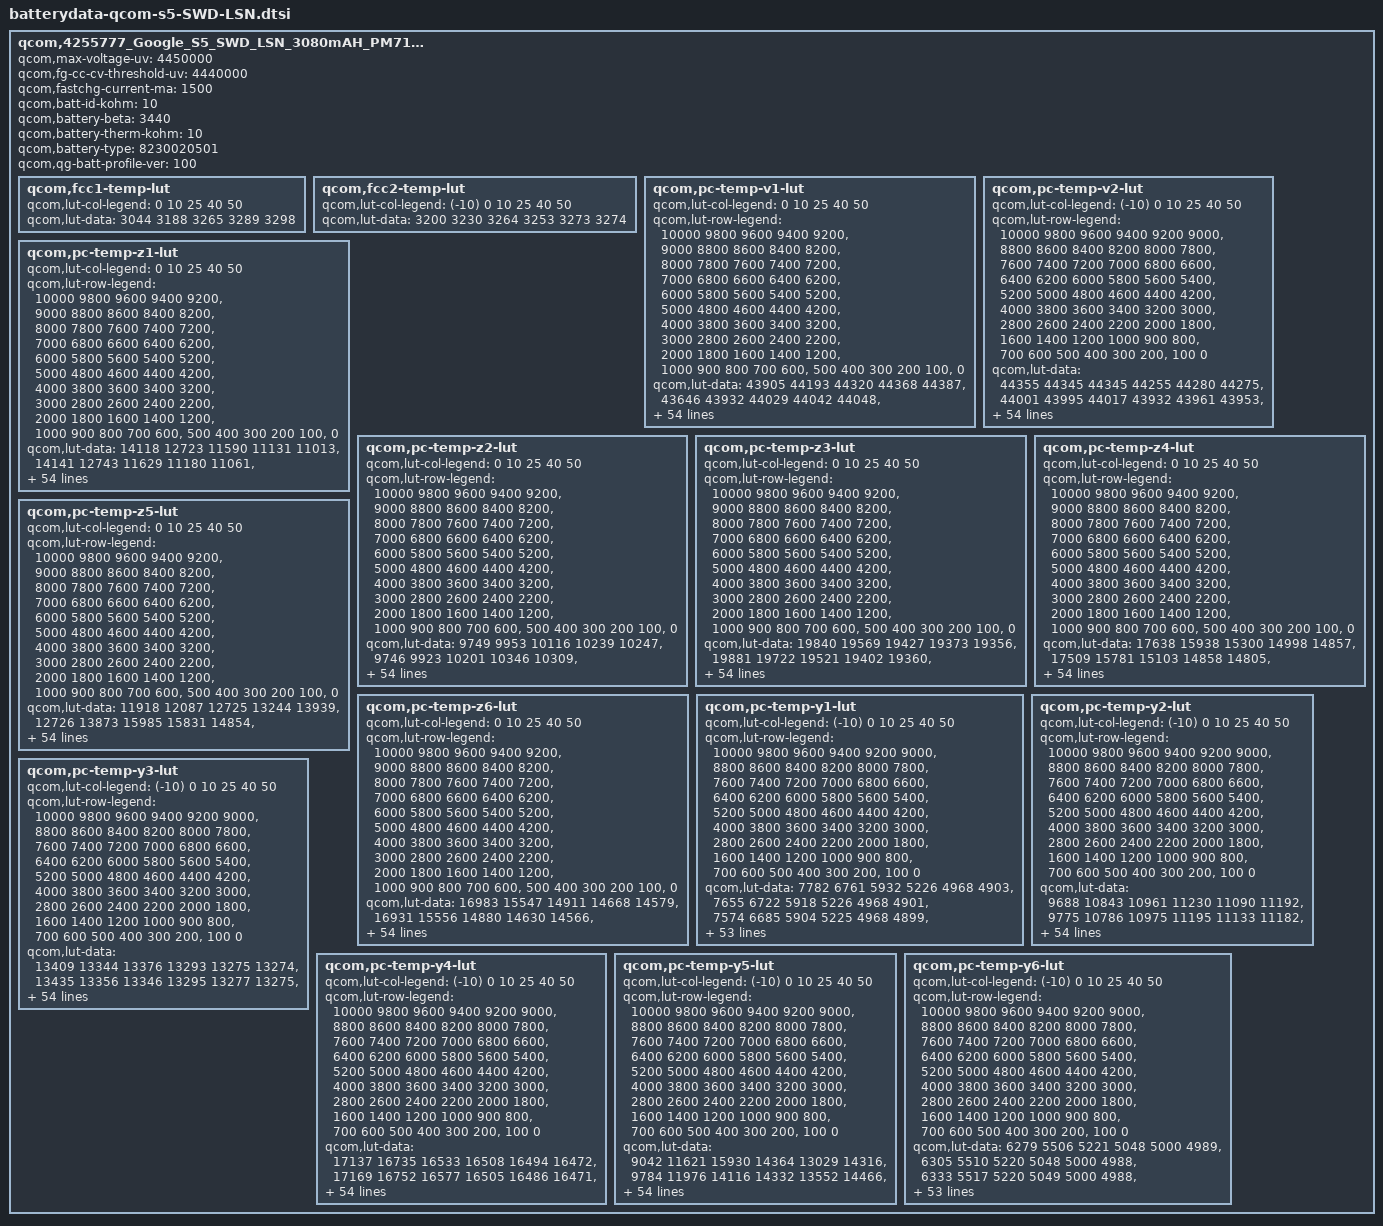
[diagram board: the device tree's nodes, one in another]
qcom,4255777_Google_S5_SWD_LSN_3080mAH_PM7150 {
	/* 4255777_Google_S5_SWD_LSN_3080mAH_PM7150_averaged_MasterSlave_Nov29th2019 */
	qcom,max-voltage-uv = <4450000>;
	qcom,fg-cc-cv-threshold-uv = <4440000>;
	qcom,fastchg-current-ma = <1500>;
	qcom,batt-id-kohm = <10>;
	qcom,battery-beta = <3440>;
	qcom,battery-therm-kohm = <10>;
	qcom,battery-type = "8230020501";
	qcom,qg-batt-profile-ver = <100>;

	qcom,fcc1-temp-lut {
		qcom,lut-col-legend = <0 10 25 40 50>;
		qcom,lut-data = <3044 3188 3265 3289 3298>;
	};

	qcom,fcc2-temp-lut {
		qcom,lut-col-legend = <(-10) 0 10 25 40 50>;
		qcom,lut-data = <3200 3230 3264 3253 3273 3274>;
	};

	qcom,pc-temp-v1-lut {
		qcom,lut-col-legend = <0 10 25 40 50>;
		qcom,lut-row-legend = <10000 9800 9600 9400 9200>,
			<9000 8800 8600 8400 8200>,
			<8000 7800 7600 7400 7200>,
			<7000 6800 6600 6400 6200>,
			<6000 5800 5600 5400 5200>,
			<5000 4800 4600 4400 4200>,
			<4000 3800 3600 3400 3200>,
			<3000 2800 2600 2400 2200>,
			<2000 1800 1600 1400 1200>,
			<1000 900 800 700 600>,
			<500 400 300 200 100>,
			<0>;
		qcom,lut-data = <43905 44193 44320 44368 44387>,
			<43646 43932 44029 44042 44048>,
			<43385 43682 43787 43791 43786>,
			<43121 43444 43556 43562 43558>,
			<42857 43207 43317 43334 43328>,
			<42599 42958 43068 43093 43096>,
			<42345 42705 42819 42849 42857>,
			<42097 42455 42567 42601 42610>,
			<41857 42207 42316 42353 42362>,
			<41624 41963 42067 42103 42117>,
			<41396 41723 41822 41856 41875>,
			<41173 41487 41582 41617 41634>,
			<40956 41259 41348 41382 41396>,
			<40749 41036 41120 41152 41164>,
			<40548 40818 40898 40928 40938>,
			<40358 40605 40684 40711 40720>,
			<40176 40401 40476 40501 40511>,
			<40002 40211 40279 40301 40311>,
			<39836 40031 40096 40114 40122>,
			<39678 39857 39920 39935 39941>,
			<39528 39690 39753 39761 39764>,
			<39384 39528 39592 39595 39595>,
			<39248 39375 39400 39413 39415>,
			<39119 39222 39129 39174 39188>,
			<38996 39052 38889 38940 38958>,
			<38880 38860 38751 38789 38796>,
			<38771 38696 38646 38677 38669>,
			<38670 38565 38546 38568 38557>,
			<38579 38456 38454 38461 38454>,
			<38496 38367 38370 38364 38360>,
			<38424 38293 38293 38278 38272>,
			<38359 38230 38223 38201 38192>,
			<38304 38176 38162 38133 38121>,
			<38256 38131 38108 38072 38056>,
			<38216 38096 38062 38020 37998>,
			<38176 38066 38024 37974 37947>,
			<38138 38034 37984 37928 37892>,
			<38098 38001 37945 37878 37826>,
			<38048 37959 37899 37819 37750>,
			<37988 37891 37827 37743 37669>,
			<37913 37800 37722 37643 37579>,
			<37813 37695 37610 37533 37473>,
			<37689 37568 37483 37407 37343>,
			<37536 37422 37334 37259 37193>,
			<37376 37267 37178 37104 37039>,
			<37238 37151 37072 37006 36947>,
			<37186 37113 37042 36978 36919>,
			<37143 37077 37021 36958 36902>,
			<37101 37045 36999 36941 36885>,
			<37057 37007 36961 36900 36835>,
			<36986 36879 36764 36684 36602>,
			<36739 36494 36340 36252 36164>,
			<36223 35896 35759 35682 35591>,
			<35437 35046 34947 34900 34801>,
			<33886 33467 33686 33694 33589>,
			<30000 30000 30000 30000 30000>;
	};

	qcom,pc-temp-v2-lut {
		qcom,lut-col-legend = <(-10) 0 10 25 40 50>;
		qcom,lut-row-legend = <10000 9800 9600 9400 9200 9000>,
			<8800 8600 8400 8200 8000 7800>,
			<7600 7400 7200 7000 6800 6600>,
			<6400 6200 6000 5800 5600 5400>,
			<5200 5000 4800 4600 4400 4200>,
			<4000 3800 3600 3400 3200 3000>,
			<2800 2600 2400 2200 2000 1800>,
			<1600 1400 1200 1000 900 800>,
			<700 600 500 400 300 200>,
			<100 0>;
		qcom,lut-data = <44355 44345 44345 44255 44280 44275>,
			<44001 43995 44017 43932 43961 43953>,
			<43689 43683 43721 43637 43669 43659>,
			<43426 43417 43462 43377 43412 43401>,
			<43206 43188 43235 43145 43183 43172>,
			<42977 42953 43001 42908 42947 42937>,
			<42727 42703 42756 42659 42701 42693>,
			<42472 42453 42510 42411 42454 42447>,
			<42217 42205 42260 42163 42206 42201>,
			<41961 41958 42009 41917 41960 41955>,
			<41710 41714 41764 41675 41718 41714>,
			<41463 41473 41524 41436 41478 41475>,
			<41217 41232 41288 41204 41245 41243>,
			<40969 40989 41054 40978 41017 41013>,
			<40721 40747 40825 40759 40796 40792>,
			<40478 40506 40600 40547 40582 40579>,
			<40235 40266 40378 40341 40374 40374>,
			<40002 40033 40150 40146 40176 40176>,
			<39780 39807 39912 39964 39989 39988>,
			<39569 39595 39682 39772 39804 39804>,
			<39373 39404 39463 39552 39626 39631>,
			<39188 39226 39259 39326 39439 39451>,
			<39013 39056 39079 39114 39209 39219>,
			<38844 38894 38915 38911 38962 38966>,
			<38686 38744 38765 38745 38780 38782>,
			<38539 38608 38628 38611 38641 38646>,
			<38401 38481 38503 38493 38520 38526>,
			<38270 38364 38390 38386 38410 38415>,
			<38142 38255 38287 38288 38312 38315>,
			<38036 38150 38191 38197 38222 38222>,
			<37953 38050 38102 38114 38140 38136>,
			<37882 37960 38019 38039 38065 38060>,
			<37820 37883 37942 37973 37997 37993>,
			<37764 37815 37871 37909 37931 37927>,
			<37709 37756 37804 37846 37870 37864>,
			<37652 37705 37742 37783 37806 37795>,
			<37594 37657 37689 37716 37719 37695>,
			<37536 37611 37643 37644 37611 37567>,
			<37474 37563 37591 37570 37514 37458>,
			<37408 37508 37529 37497 37428 37367>,
			<37336 37442 37455 37419 37350 37288>,
			<37260 37358 37364 37333 37270 37209>,
			<37177 37253 37262 37215 37150 37089>,
			<37083 37132 37138 37098 37032 36971>,
			<36981 36999 36981 36933 36878 36821>,
			<36854 36895 36886 36879 36835 36782>,
			<36783 36843 36853 36867 36821 36768>,
			<36706 36790 36820 36851 36805 36750>,
			<36617 36733 36780 36820 36777 36722>,
			<36504 36658 36717 36757 36703 36638>,
			<36336 36531 36546 36531 36422 36330>,
			<36070 36245 36095 36042 35931 35833>,
			<35571 35702 35379 35387 35275 35174>,
			<34436 34269 34394 34468 34359 34255>,
			<32847 32695 32391 33002 32911 32789>,
			<30279 31619 29790 28145 28395 28310>;
	};

	qcom,pc-temp-z1-lut {
		qcom,lut-col-legend = <0 10 25 40 50>;
		qcom,lut-row-legend = <10000 9800 9600 9400 9200>,
			<9000 8800 8600 8400 8200>,
			<8000 7800 7600 7400 7200>,
			<7000 6800 6600 6400 6200>,
			<6000 5800 5600 5400 5200>,
			<5000 4800 4600 4400 4200>,
			<4000 3800 3600 3400 3200>,
			<3000 2800 2600 2400 2200>,
			<2000 1800 1600 1400 1200>,
			<1000 900 800 700 600>,
			<500 400 300 200 100>,
			<0>;
		qcom,lut-data = <14118 12723 11590 11131 11013>,
			<14141 12743 11629 11180 11061>,
			<14150 12717 11630 11181 11064>,
			<14147 12717 11608 11178 11063>,
			<14137 12715 11600 11173 11060>,
			<14123 12696 11595 11172 11061>,
			<14097 12666 11592 11172 11061>,
			<14061 12640 11589 11171 11060>,
			<14004 12615 11586 11170 11060>,
			<13927 12601 11584 11170 11060>,
			<13861 12596 11583 11170 11060>,
			<13792 12593 11582 11170 11061>,
			<13737 12595 11582 11170 11062>,
			<13699 12607 11583 11170 11062>,
			<13668 12614 11584 11170 11062>,
			<13658 12615 11585 11170 11062>,
			<13660 12617 11586 11171 11063>,
			<13669 12627 11589 11172 11063>,
			<13688 12642 11591 11173 11064>,
			<13718 12653 11595 11175 11066>,
			<13735 12662 11600 11176 11067>,
			<13743 12673 11604 11178 11068>,
			<13749 12683 11609 11180 11069>,
			<13763 12693 11614 11182 11071>,
			<13785 12705 11619 11184 11074>,
			<13791 12719 11624 11187 11077>,
			<13774 12726 11629 11191 11080>,
			<13759 12726 11634 11195 11083>,
			<13772 12728 11639 11197 11086>,
			<13805 12737 11645 11200 11088>,
			<13822 12753 11653 11202 11090>,
			<13826 12769 11661 11205 11092>,
			<13831 12798 11665 11208 11093>,
			<13849 12818 11668 11211 11095>,
			<13886 12815 11674 11215 11097>,
			<13909 12809 11688 11219 11100>,
			<13915 12811 11699 11223 11104>,
			<13923 12830 11705 11227 11106>,
			<13950 12849 11711 11230 11108>,
			<14015 12859 11720 11233 11111>,
			<14063 12869 11730 11236 11114>,
			<14084 12894 11737 11238 11116>,
			<14101 12936 11741 11241 11116>,
			<14120 12947 11747 11244 11118>,
			<14133 12945 11753 11246 11120>,
			<14099 12961 11756 11250 11119>,
			<14130 12960 11759 11251 11121>,
			<14087 12955 11761 11249 11121>,
			<14179 12969 11761 11250 11122>,
			<14105 12955 11775 11256 11125>,
			<14190 12961 11786 11262 11130>,
			<14205 12982 11797 11271 11137>,
			<14176 13026 11821 11283 11147>,
			<14211 13039 11860 11301 11160>,
			<14211 13039 11860 11301 11160>,
			<14211 13039 11860 11301 11160>;
	};

	qcom,pc-temp-z2-lut {
		qcom,lut-col-legend = <0 10 25 40 50>;
		qcom,lut-row-legend = <10000 9800 9600 9400 9200>,
			<9000 8800 8600 8400 8200>,
			<8000 7800 7600 7400 7200>,
			<7000 6800 6600 6400 6200>,
			<6000 5800 5600 5400 5200>,
			<5000 4800 4600 4400 4200>,
			<4000 3800 3600 3400 3200>,
			<3000 2800 2600 2400 2200>,
			<2000 1800 1600 1400 1200>,
			<1000 900 800 700 600>,
			<500 400 300 200 100>,
			<0>;
		qcom,lut-data = <9749 9953 10116 10239 10247>,
			<9746 9923 10201 10346 10309>,
			<9746 10002 10231 10410 10345>,
			<9759 10016 10173 10398 10334>,
			<9782 10023 10130 10344 10407>,
			<9805 10031 10111 10334 10385>,
			<9856 10037 10115 10332 10368>,
			<9892 10038 10132 10333 10359>,
			<9899 10037 10147 10337 10348>,
			<9903 10036 10161 10352 10315>,
			<9909 10037 10176 10367 10279>,
			<9917 10038 10195 10366 10277>,
			<9925 10034 10215 10361 10286>,
			<9934 10018 10235 10352 10295>,
			<9943 10006 10254 10331 10305>,
			<9944 9999 10269 10319 10319>,
			<9939 9994 10282 10332 10345>,
			<9932 10023 10295 10353 10377>,
			<9924 10090 10311 10376 10399>,
			<9914 10107 10326 10407 10417>,
			<9912 10069 10333 10421 10423>,
			<9918 10042 10338 10431 10425>,
			<9927 10054 10338 10432 10428>,
			<9935 10072 10318 10385 10465>,
			<9944 10088 10296 10330 10515>,
			<9957 10102 10284 10374 10518>,
			<9987 10108 10273 10500 10508>,
			<10026 10107 10276 10528 10485>,
			<10070 10106 10300 10463 10382>,
			<10124 10107 10317 10403 10300>,
			<10175 10112 10327 10373 10282>,
			<10230 10116 10332 10354 10272>,
			<10269 10121 10325 10357 10279>,
			<10213 10127 10310 10372 10311>,
			<10017 10132 10307 10394 10346>,
			<9898 10138 10310 10440 10388>,
			<9734 10147 10314 10484 10435>,
			<9544 10161 10323 10517 10492>,
			<9478 10174 10336 10542 10542>,
			<9431 10184 10358 10555 10547>,
			<9412 10193 10386 10565 10537>,
			<9417 10200 10390 10564 10532>,
			<9428 10208 10375 10544 10536>,
			<9458 10228 10373 10543 10522>,
			<9457 10295 10390 10553 10492>,
			<9450 10552 10477 10527 10544>,
			<9449 10602 10482 10503 10516>,
			<9437 10639 10515 10492 10532>,
			<9445 10643 10658 10542 10565>,
			<9431 10629 10624 10658 10651>,
			<9383 10575 10670 10599 10515>,
			<9423 10442 10684 10470 10367>,
			<9455 10248 10554 10356 10307>,
			<9977 10105 10261 10262 10201>,
			<9977 10105 10261 10262 10201>,
			<9977 10105 10261 10262 10201>;
	};

	qcom,pc-temp-z3-lut {
		qcom,lut-col-legend = <0 10 25 40 50>;
		qcom,lut-row-legend = <10000 9800 9600 9400 9200>,
			<9000 8800 8600 8400 8200>,
			<8000 7800 7600 7400 7200>,
			<7000 6800 6600 6400 6200>,
			<6000 5800 5600 5400 5200>,
			<5000 4800 4600 4400 4200>,
			<4000 3800 3600 3400 3200>,
			<3000 2800 2600 2400 2200>,
			<2000 1800 1600 1400 1200>,
			<1000 900 800 700 600>,
			<500 400 300 200 100>,
			<0>;
		qcom,lut-data = <19840 19569 19427 19373 19356>,
			<19881 19722 19521 19402 19360>,
			<19918 19836 19511 19403 19366>,
			<19956 19829 19592 19446 19381>,
			<19989 19817 19602 19465 19431>,
			<20006 19798 19605 19461 19420>,
			<20017 19768 19596 19453 19413>,
			<20023 19744 19569 19438 19411>,
			<20019 19720 19549 19428 19408>,
			<20009 19705 19535 19424 19396>,
			<19997 19696 19521 19421 19381>,
			<19980 19691 19506 19410 19375>,
			<19961 19689 19492 19391 19371>,
			<19940 19689 19484 19383 19368>,
			<19918 19689 19478 19378 19367>,
			<19898 19690 19474 19376 19364>,
			<19877 19692 19472 19375 19358>,
			<19860 19693 19470 19375 19349>,
			<19847 19693 19465 19375 19345>,
			<19835 19688 19460 19373 19342>,
			<19823 19662 19460 19372 19342>,
			<19810 19642 19461 19373 19346>,
			<19796 19641 19465 19373 19349>,
			<19781 19641 19490 19369 19340>,
			<19765 19651 19510 19364 19328>,
			<19757 19690 19500 19363 19340>,
			<19760 19711 19480 19361 19381>,
			<19770 19706 19468 19365 19394>,
			<19782 19697 19459 19397 19386>,
			<19798 19691 19456 19418 19378>,
			<19804 19685 19460 19415 19374>,
			<19788 19680 19467 19410 19371>,
			<19757 19676 19475 19405 19367>,
			<19700 19672 19482 19399 19363>,
			<19597 19665 19484 19394 19358>,
			<19525 19654 19483 19389 19352>,
			<19488 19645 19482 19386 19349>,
			<19458 19637 19478 19383 19352>,
			<19429 19631 19473 19382 19356>,
			<19399 19629 19470 19380 19355>,
			<19384 19627 19468 19378 19350>,
			<19382 19621 19464 19375 19347>,
			<19380 19608 19461 19371 19346>,
			<19378 19588 19458 19370 19348>,
			<19364 19556 19453 19370 19351>,
			<19355 19379 19430 19355 19336>,
			<19353 19317 19421 19355 19335>,
			<19343 19309 19405 19353 19331>,
			<19342 19300 19373 19347 19323>,
			<19342 19294 19382 19330 19321>,
			<19320 19300 19370 19341 19329>,
			<19352 19329 19356 19354 19341>,
			<19399 19519 19364 19368 19346>,
			<19691 19576 19446 19376 19363>,
			<19691 19576 19446 19376 19363>,
			<19691 19576 19446 19376 19363>;
	};

	qcom,pc-temp-z4-lut {
		qcom,lut-col-legend = <0 10 25 40 50>;
		qcom,lut-row-legend = <10000 9800 9600 9400 9200>,
			<9000 8800 8600 8400 8200>,
			<8000 7800 7600 7400 7200>,
			<7000 6800 6600 6400 6200>,
			<6000 5800 5600 5400 5200>,
			<5000 4800 4600 4400 4200>,
			<4000 3800 3600 3400 3200>,
			<3000 2800 2600 2400 2200>,
			<2000 1800 1600 1400 1200>,
			<1000 900 800 700 600>,
			<500 400 300 200 100>,
			<0>;
		qcom,lut-data = <17638 15938 15300 14998 14857>,
			<17509 15781 15103 14858 14805>,
			<17303 16447 14936 14796 14759>,
			<16951 16136 15161 14838 14753>,
			<16519 15766 15078 14870 14811>,
			<16219 15582 14963 14812 14779>,
			<15994 15445 14906 14792 14760>,
			<15817 15342 14866 14788 14750>,
			<15679 15264 14846 14783 14746>,
			<15567 15195 14836 14772 14747>,
			<15478 15125 14829 14762 14748>,
			<15405 15063 14824 14763 14746>,
			<15343 15023 14819 14766 14738>,
			<15286 14993 14811 14766 14730>,
			<15237 14965 14800 14758 14721>,
			<15216 14937 14788 14749 14713>,
			<15205 14910 14777 14739 14710>,
			<15200 14879 14766 14728 14708>,
			<15199 14844 14758 14718 14703>,
			<15199 14833 14751 14709 14695>,
			<15199 14845 14744 14707 14693>,
			<15203 14852 14737 14708 14694>,
			<15208 14841 14741 14712 14695>,
			<15218 14828 14813 14786 14760>,
			<15235 14827 14874 14875 14851>,
			<15244 14832 14874 14878 14843>,
			<15238 14840 14870 14861 14785>,
			<15227 14857 14865 14835 14754>,
			<15209 14872 14853 14784 14745>,
			<15182 14872 14838 14745 14738>,
			<15173 14868 14818 14730 14727>,
			<15182 14862 14796 14721 14716>,
			<15201 14853 14776 14715 14707>,
			<15252 14841 14758 14710 14699>,
			<15360 14829 14746 14708 14697>,
			<15421 14817 14736 14709 14698>,
			<15435 14804 14731 14709 14701>,
			<15438 14791 14727 14713 14710>,
			<15427 14779 14725 14719 14721>,
			<15401 14768 14727 14722 14721>,
			<15371 14759 14732 14724 14718>,
			<15333 14754 14732 14723 14713>,
			<15289 14751 14720 14712 14702>,
			<15247 14752 14712 14709 14698>,
			<15131 14747 14704 14708 14697>,
			<15077 14863 14676 14684 14679>,
			<15080 14930 14678 14675 14670>,
			<15080 14931 14681 14659 14657>,
			<15077 14932 14701 14649 14642>,
			<15071 14930 14686 14659 14640>,
			<15086 14926 14714 14668 14655>,
			<15074 14935 14746 14665 14652>,
			<15100 14770 14744 14652 14649>,
			<14890 14813 14679 14652 14642>,
			<14890 14813 14679 14652 14642>,
			<14890 14813 14679 14652 14642>;
	};

	qcom,pc-temp-z5-lut {
		qcom,lut-col-legend = <0 10 25 40 50>;
		qcom,lut-row-legend = <10000 9800 9600 9400 9200>,
			<9000 8800 8600 8400 8200>,
			<8000 7800 7600 7400 7200>,
			<7000 6800 6600 6400 6200>,
			<6000 5800 5600 5400 5200>,
			<5000 4800 4600 4400 4200>,
			<4000 3800 3600 3400 3200>,
			<3000 2800 2600 2400 2200>,
			<2000 1800 1600 1400 1200>,
			<1000 900 800 700 600>,
			<500 400 300 200 100>,
			<0>;
		qcom,lut-data = <11918 12087 12725 13244 13939>,
			<12726 13873 15985 15831 14854>,
			<13624 13147 17440 17496 16998>,
			<14654 13388 15264 18312 18281>,
			<15751 13703 15818 17216 18591>,
			<16793 13937 16527 18010 18581>,
			<17826 14148 16772 18070 18617>,
			<18718 14236 16922 17282 18803>,
			<19425 14235 16926 16839 18926>,
			<20019 14256 16683 17001 18005>,
			<20495 14435 16401 17180 16680>,
			<20940 14704 16073 16714 16522>,
			<21172 14897 15800 15581 16563>,
			<21110 15047 15832 15302 16658>,
			<20923 15278 16035 15395 17008>,
			<20603 15815 16319 15550 17248>,
			<19762 16426 16817 15935 16888>,
			<18841 17210 17334 16475 16375>,
			<18225 18345 17719 17030 16411>,
			<17699 18554 18141 17709 16801>,
			<17200 17839 18773 18298 17417>,
			<16713 17487 19755 19074 18828>,
			<16270 17990 21764 19459 19716>,
			<15857 18952 29164 18604 17544>,
			<15471 22389 34832 17147 14449>,
			<15262 32458 31036 15867 14683>,
			<15320 37464 23647 14616 16481>,
			<15502 35369 20405 14593 17208>,
			<15709 32226 18615 16898 17240>,
			<15962 30202 18087 19204 17301>,
			<16039 28538 18390 20452 17865>,
			<15658 27543 18989 21487 18872>,
			<14998 27015 20320 22517 19955>,
			<14170 26510 22572 23535 21214>,
			<13038 25593 24632 24488 21928>,
			<12293 24567 26795 25522 22261>,
			<11935 24199 27735 26018 22544>,
			<11673 24035 27748 25625 22976>,
			<11427 23980 27665 24814 23351>,
			<11178 25178 27233 23769 22737>,
			<11077 26747 26309 22352 20668>,
			<11090 26315 25721 21459 19889>,
			<11120 24120 25380 20900 20018>,
			<11213 21585 25094 20430 20088>,
			<11489 20517 24913 19894 20009>,
			<11598 14908 25266 19605 18655>,
			<11545 11738 22509 19899 18975>,
			<11438 11613 18865 20825 19280>,
			<11395 11479 15739 20762 19793>,
			<11387 11425 17027 17007 19753>,
			<11252 11524 15187 16963 17556>,
			<11448 11783 13478 17685 18539>,
			<11898 18648 13654 20485 19332>,
			<19529 18976 23613 22236 26765>,
			<19529 18976 23613 22236 26765>,
			<19529 18976 23613 22236 26765>;
	};

	qcom,pc-temp-z6-lut {
		qcom,lut-col-legend = <0 10 25 40 50>;
		qcom,lut-row-legend = <10000 9800 9600 9400 9200>,
			<9000 8800 8600 8400 8200>,
			<8000 7800 7600 7400 7200>,
			<7000 6800 6600 6400 6200>,
			<6000 5800 5600 5400 5200>,
			<5000 4800 4600 4400 4200>,
			<4000 3800 3600 3400 3200>,
			<3000 2800 2600 2400 2200>,
			<2000 1800 1600 1400 1200>,
			<1000 900 800 700 600>,
			<500 400 300 200 100>,
			<0>;
		qcom,lut-data = <16983 15547 14911 14668 14579>,
			<16931 15556 14880 14630 14566>,
			<16848 15890 14802 14602 14549>,
			<16696 15749 14937 14643 14554>,
			<16504 15576 14906 14669 14606>,
			<16366 15476 14859 14643 14587>,
			<16262 15395 14825 14627 14575>,
			<16172 15332 14795 14617 14570>,
			<16092 15280 14775 14610 14566>,
			<16021 15238 14763 14603 14559>,
			<15955 15203 14752 14597 14553>,
			<15894 15174 14742 14590 14547>,
			<15838 15157 14733 14583 14542>,
			<15783 15146 14724 14577 14537>,
			<15734 15136 14717 14572 14533>,
			<15711 15125 14710 14567 14528>,
			<15699 15115 14703 14562 14522>,
			<15693 15104 14698 14557 14517>,
			<15694 15093 14691 14552 14512>,
			<15699 15085 14686 14547 14508>,
			<15702 15079 14685 14546 14506>,
			<15706 15075 14684 14547 14508>,
			<15709 15073 14687 14549 14511>,
			<15715 15071 14731 14580 14536>,
			<15723 15075 14769 14616 14569>,
			<15729 15100 14765 14617 14572>,
			<15734 15117 14755 14610 14569>,
			<15738 15125 14747 14603 14565>,
			<15742 15129 14738 14598 14558>,
			<15746 15128 14731 14592 14550>,
			<15747 15125 14725 14585 14544>,
			<15746 15123 14721 14578 14537>,
			<15745 15120 14717 14573 14531>,
			<15743 15116 14714 14568 14525>,
			<15741 15111 14711 14564 14522>,
			<15740 15103 14709 14562 14519>,
			<15743 15097 14706 14561 14518>,
			<15747 15091 14704 14562 14523>,
			<15752 15088 14702 14564 14530>,
			<15757 15086 14703 14564 14530>,
			<15760 15085 14705 14564 14527>,
			<15758 15084 14705 14563 14523>,
			<15754 15081 14699 14556 14518>,
			<15742 15076 14695 14555 14517>,
			<15692 15059 14690 14554 14519>,
			<15664 15021 14668 14537 14503>,
			<15665 15019 14664 14533 14499>,
			<15664 15017 14657 14525 14491>,
			<15661 15015 14652 14517 14480>,
			<15664 15016 14652 14514 14479>,
			<15669 15024 14660 14525 14491>,
			<15691 15052 14670 14532 14497>,
			<15738 15093 14681 14537 14501>,
			<15822 15161 14705 14544 14510>,
			<15822 15161 14705 14544 14510>,
			<15822 15161 14705 14544 14510>;
	};

	qcom,pc-temp-y1-lut {
		qcom,lut-col-legend = <(-10) 0 10 25 40 50>;
		qcom,lut-row-legend = <10000 9800 9600 9400 9200 9000>,
			<8800 8600 8400 8200 8000 7800>,
			<7600 7400 7200 7000 6800 6600>,
			<6400 6200 6000 5800 5600 5400>,
			<5200 5000 4800 4600 4400 4200>,
			<4000 3800 3600 3400 3200 3000>,
			<2800 2600 2400 2200 2000 1800>,
			<1600 1400 1200 1000 900 800>,
			<700 600 500 400 300 200>,
			<100 0>;
		qcom,lut-data = <7782 6761 5932 5226 4968 4903>,
			<7655 6722 5918 5226 4968 4901>,
			<7574 6685 5904 5225 4968 4899>,
			<7529 6656 5892 5223 4968 4898>,
			<7510 6636 5884 5222 4968 4898>,
			<7508 6630 5881 5221 4968 4898>,
			<7552 6638 5884 5220 4967 4901>,
			<7597 6648 5886 5218 4965 4902>,
			<7587 6650 5884 5217 4964 4901>,
			<7557 6648 5880 5215 4963 4899>,
			<7547 6644 5876 5213 4963 4899>,
			<7545 6630 5870 5212 4963 4900>,
			<7545 6615 5865 5211 4964 4901>,
			<7538 6600 5859 5209 4963 4899>,
			<7532 6587 5855 5208 4963 4898>,
			<7547 6589 5854 5209 4964 4899>,
			<7577 6599 5854 5210 4965 4900>,
			<7588 6603 5857 5211 4966 4901>,
			<7549 6601 5867 5212 4966 4902>,
			<7507 6599 5872 5214 4966 4902>,
			<7514 6607 5865 5216 4966 4902>,
			<7540 6619 5856 5219 4966 4903>,
			<7553 6622 5856 5220 4967 4903>,
			<7561 6622 5858 5221 4969 4903>,
			<7565 6623 5859 5223 4970 4903>,
			<7571 6632 5859 5226 4968 4904>,
			<7581 6642 5861 5228 4966 4905>,
			<7578 6642 5865 5231 4970 4905>,
			<7556 6639 5871 5233 4974 4906>,
			<7546 6639 5876 5235 4976 4907>,
			<7539 6641 5887 5237 4978 4908>,
			<7525 6643 5890 5240 4979 4910>,
			<7511 6645 5891 5244 4979 4911>,
			<7499 6649 5892 5248 4980 4913>,
			<7495 6648 5891 5250 4983 4915>,
			<7498 6646 5887 5251 4986 4916>,
			<7501 6645 5888 5254 4986 4917>,
			<7499 6642 5891 5259 4985 4917>,
			<7498 6641 5893 5262 4986 4917>,
			<7505 6652 5900 5263 4986 4918>,
			<7524 6669 5904 5264 4988 4919>,
			<7514 6673 5907 5265 4992 4922>,
			<7512 6686 5911 5269 4990 4922>,
			<7565 6647 5912 5275 4995 4924>,
			<7538 6683 5942 5279 4996 4926>,
			<7567 6678 5926 5284 4998 4927>,
			<7570 6697 5934 5284 5000 4928>,
			<7544 6690 5953 5286 5002 4928>,
			<7546 6697 5959 5291 5001 4928>,
			<7559 6696 5955 5295 5004 4928>,
			<7540 6699 5962 5298 5004 4931>,
			<7590 6693 5981 5313 5011 4936>,
			<7691 6804 5993 5334 5020 4943>,
			<8136 7126 6131 5374 5034 4957>,
			<8136 7126 6131 5374 5034 4957>,
			<8136 7126 6131 5374 5034 4957>;
	};

	qcom,pc-temp-y2-lut {
		qcom,lut-col-legend = <(-10) 0 10 25 40 50>;
		qcom,lut-row-legend = <10000 9800 9600 9400 9200 9000>,
			<8800 8600 8400 8200 8000 7800>,
			<7600 7400 7200 7000 6800 6600>,
			<6400 6200 6000 5800 5600 5400>,
			<5200 5000 4800 4600 4400 4200>,
			<4000 3800 3600 3400 3200 3000>,
			<2800 2600 2400 2200 2000 1800>,
			<1600 1400 1200 1000 900 800>,
			<700 600 500 400 300 200>,
			<100 0>;
		qcom,lut-data = <9688 10843 10961 11230 11090 11192>,
			<9775 10786 10975 11195 11133 11182>,
			<9943 10726 10969 11160 11147 11168>,
			<10132 10669 10947 11126 11144 11151>,
			<10282 10623 10913 11093 11131 11133>,
			<10335 10592 10869 11063 11115 11114>,
			<10340 10568 10798 11034 11070 11073>,
			<10345 10555 10742 11008 11038 11040>,
			<10355 10554 10725 10981 11056 11030>,
			<10372 10553 10714 10956 11084 11018>,
			<10387 10554 10700 10954 11078 10990>,
			<10402 10558 10684 10963 11036 10928>,
			<10417 10565 10678 10967 11010 10905>,
			<10435 10577 10680 10934 11000 10941>,
			<10454 10594 10684 10901 10991 10974>,
			<10470 10609 10693 10900 10976 10968>,
			<10486 10625 10711 10904 10961 10953>,
			<10498 10643 10730 10915 10967 10956>,
			<10505 10668 10752 10961 11014 10976>,
			<10511 10688 10776 10988 11071 11008>,
			<10517 10699 10801 10982 11154 11096>,
			<10522 10707 10829 10973 11213 11173>,
			<10525 10721 10862 10992 11193 11168>,
			<10526 10743 10898 11051 11150 11141>,
			<10527 10758 10922 11086 11145 11137>,
			<10524 10766 10942 11107 11169 11141>,
			<10514 10772 10953 11120 11193 11153>,
			<10409 10775 10948 11122 11211 11189>,
			<9990 10779 10940 11123 11224 11237>,
			<9750 10785 10936 11126 11230 11282>,
			<9719 10799 10928 11131 11235 11326>,
			<9703 10809 10925 11132 11245 11349>,
			<9693 10811 10922 11124 11265 11361>,
			<9686 10811 10918 11113 11277 11373>,
			<9681 10807 10923 11098 11259 11389>,
			<9676 10795 10932 11078 11238 11400>,
			<9672 10779 10926 11068 11244 11368>,
			<9668 10749 10902 11061 11259 11293>,
			<9665 10714 10889 11058 11256 11267>,
			<9662 10685 10882 11073 11238 11261>,
			<9659 10654 10871 11081 11200 11235>,
			<9658 10611 10851 11067 11155 11211>,
			<9656 10552 10836 11040 11207 11238>,
			<9656 10560 10861 11068 11225 11242>,
			<9655 10459 10853 11186 11157 11184>,
			<9654 10335 10798 11140 11104 11120>,
			<9653 10089 10728 11025 11147 11095>,
			<9653 9751 10647 10997 11107 11119>,
			<9652 9680 10566 10968 11088 11041>,
			<9652 9663 10465 10969 11022 11001>,
			<9651 9655 10307 10939 11031 10982>,
			<9650 9651 9778 10908 10990 10889>,
			<9649 9648 9654 10752 10895 10825>,
			<9648 9647 9649 10600 10826 10708>,
			<9648 9647 9649 10600 10826 10708>,
			<9648 9647 9649 10600 10826 10708>;
	};

	qcom,pc-temp-y3-lut {
		qcom,lut-col-legend = <(-10) 0 10 25 40 50>;
		qcom,lut-row-legend = <10000 9800 9600 9400 9200 9000>,
			<8800 8600 8400 8200 8000 7800>,
			<7600 7400 7200 7000 6800 6600>,
			<6400 6200 6000 5800 5600 5400>,
			<5200 5000 4800 4600 4400 4200>,
			<4000 3800 3600 3400 3200 3000>,
			<2800 2600 2400 2200 2000 1800>,
			<1600 1400 1200 1000 900 800>,
			<700 600 500 400 300 200>,
			<100 0>;
		qcom,lut-data = <13409 13344 13376 13293 13275 13274>,
			<13435 13356 13346 13295 13277 13275>,
			<13481 13371 13329 13297 13279 13276>,
			<13532 13384 13320 13299 13281 13278>,
			<13572 13395 13317 13300 13282 13279>,
			<13587 13401 13318 13302 13283 13280>,
			<13590 13404 13333 13303 13284 13281>,
			<13591 13407 13345 13303 13284 13282>,
			<13590 13412 13344 13303 13285 13282>,
			<13588 13419 13343 13303 13286 13283>,
			<13587 13425 13345 13302 13286 13283>,
			<13587 13431 13355 13301 13285 13283>,
			<13587 13433 13362 13301 13285 13283>,
			<13580 13432 13365 13305 13289 13283>,
			<13566 13429 13368 13311 13293 13283>,
			<13557 13426 13371 13314 13292 13285>,
			<13549 13421 13373 13316 13290 13288>,
			<13541 13415 13373 13318 13291 13289>,
			<13532 13406 13368 13321 13294 13288>,
			<13523 13400 13361 13322 13296 13288>,
			<13515 13398 13354 13319 13299 13291>,
			<13508 13396 13346 13315 13301 13295>,
			<13500 13393 13341 13310 13297 13290>,
			<13490 13387 13337 13302 13289 13279>,
			<13482 13383 13334 13299 13284 13277>,
			<13475 13383 13331 13298 13281 13277>,
			<13469 13382 13329 13298 13280 13278>,
			<13456 13382 13332 13299 13280 13277>,
			<13429 13382 13336 13300 13280 13277>,
			<13417 13381 13338 13301 13281 13277>,
			<13419 13374 13340 13301 13282 13276>,
			<13425 13369 13341 13301 13282 13276>,
			<13435 13369 13341 13304 13283 13277>,
			<13457 13369 13341 13306 13283 13278>,
			<13478 13369 13340 13305 13284 13278>,
			<13497 13370 13338 13304 13285 13279>,
			<13522 13371 13339 13303 13284 13278>,
			<13562 13380 13341 13302 13281 13277>,
			<13617 13389 13342 13302 13280 13276>,
			<13676 13395 13342 13302 13281 13276>,
			<13743 13400 13342 13302 13281 13276>,
			<13830 13405 13341 13302 13280 13277>,
			<13921 13405 13343 13301 13281 13276>,
			<13935 13384 13334 13300 13281 13277>,
			<13970 13368 13333 13289 13282 13276>,
			<14192 13392 13332 13289 13283 13278>,
			<14357 13405 13335 13301 13283 13279>,
			<14566 13435 13344 13306 13286 13281>,
			<14827 13524 13359 13305 13290 13286>,
			<15140 13670 13379 13310 13291 13287>,
			<15538 14079 13403 13308 13285 13283>,
			<16301 15343 13488 13306 13287 13284>,
			<20565 22338 14644 13315 13289 13286>,
			<46869 65535 26276 13332 13298 13291>,
			<46869 65535 26276 13332 13298 13291>,
			<46869 65535 26276 13332 13298 13291>;
	};

	qcom,pc-temp-y4-lut {
		qcom,lut-col-legend = <(-10) 0 10 25 40 50>;
		qcom,lut-row-legend = <10000 9800 9600 9400 9200 9000>,
			<8800 8600 8400 8200 8000 7800>,
			<7600 7400 7200 7000 6800 6600>,
			<6400 6200 6000 5800 5600 5400>,
			<5200 5000 4800 4600 4400 4200>,
			<4000 3800 3600 3400 3200 3000>,
			<2800 2600 2400 2200 2000 1800>,
			<1600 1400 1200 1000 900 800>,
			<700 600 500 400 300 200>,
			<100 0>;
		qcom,lut-data = <17137 16735 16533 16508 16494 16472>,
			<17169 16752 16577 16505 16486 16471>,
			<17212 16769 16614 16504 16480 16467>,
			<17256 16784 16641 16504 16476 16464>,
			<17293 16798 16657 16504 16474 16461>,
			<17316 16810 16660 16505 16474 16460>,
			<17335 16821 16645 16510 16476 16460>,
			<17347 16830 16633 16516 16479 16460>,
			<17348 16837 16644 16523 16482 16461>,
			<17347 16842 16666 16533 16486 16464>,
			<17343 16848 16678 16544 16492 16468>,
			<17330 16856 16685 16558 16501 16474>,
			<17314 16860 16695 16570 16507 16480>,
			<17304 16860 16717 16578 16509 16487>,
			<17292 16858 16741 16585 16512 16493>,
			<17269 16854 16759 16601 16522 16498>,
			<17227 16842 16774 16625 16540 16502>,
			<17183 16827 16771 16657 16557 16510>,
			<17143 16806 16740 16708 16574 16525>,
			<17105 16785 16703 16734 16596 16546>,
			<17075 16768 16664 16707 16638 16581>,
			<17050 16752 16630 16658 16669 16607>,
			<17025 16741 16613 16602 16621 16574>,
			<17000 16731 16601 16537 16519 16502>,
			<16975 16723 16597 16513 16490 16478>,
			<16947 16715 16597 16509 16484 16472>,
			<16922 16708 16596 16507 16482 16470>,
			<16929 16702 16592 16508 16485 16472>,
			<16981 16696 16589 16511 16489 16476>,
			<17020 16692 16589 16515 16495 16481>,
			<17035 16690 16591 16522 16502 16490>,
			<17045 16687 16592 16530 16511 16499>,
			<17054 16681 16592 16542 16523 16510>,
			<17063 16675 16593 16550 16533 16519>,
			<17075 16677 16589 16551 16543 16527>,
			<17098 16688 16584 16551 16550 16532>,
			<17125 16700 16585 16547 16537 16520>,
			<17151 16714 16592 16527 16497 16486>,
			<17180 16729 16599 16508 16476 16469>,
			<17215 16750 16604 16494 16468 16463>,
			<17255 16765 16606 16490 16470 16465>,
			<17283 16766 16605 16497 16480 16471>,
			<17296 16757 16594 16490 16470 16464>,
			<17228 16705 16574 16486 16473 16464>,
			<17150 16734 16559 16491 16456 16450>,
			<17200 16754 16577 16503 16468 16461>,
			<17240 16804 16599 16498 16478 16472>,
			<17289 16896 16626 16507 16490 16481>,
			<17354 16971 16665 16536 16504 16502>,
			<17480 17073 16731 16552 16520 16511>,
			<17560 17218 16792 16535 16480 16464>,
			<17633 17397 16896 16516 16477 16466>,
			<18868 18795 17289 16536 16488 16478>,
			<38490 38899 21264 16594 16528 16522>,
			<38490 38899 21264 16594 16528 16522>,
			<38490 38899 21264 16594 16528 16522>;
	};

	qcom,pc-temp-y5-lut {
		qcom,lut-col-legend = <(-10) 0 10 25 40 50>;
		qcom,lut-row-legend = <10000 9800 9600 9400 9200 9000>,
			<8800 8600 8400 8200 8000 7800>,
			<7600 7400 7200 7000 6800 6600>,
			<6400 6200 6000 5800 5600 5400>,
			<5200 5000 4800 4600 4400 4200>,
			<4000 3800 3600 3400 3200 3000>,
			<2800 2600 2400 2200 2000 1800>,
			<1600 1400 1200 1000 900 800>,
			<700 600 500 400 300 200>,
			<100 0>;
		qcom,lut-data = <9042 11621 15930 14364 13029 14316>,
			<9784 11976 14116 14332 13552 14466>,
			<10736 12334 12833 14272 13917 14779>,
			<11697 12641 12019 14191 14145 15131>,
			<12468 12846 11609 14094 14257 15400>,
			<12855 12894 11578 13984 14268 15475>,
			<13009 12794 12228 13794 14127 15481>,
			<13121 12701 12763 13550 13930 15483>,
			<13233 12811 12548 13273 13748 15347>,
			<13338 13110 12178 12955 13535 15035>,
			<13513 13421 12214 12614 13231 14701>,
			<13881 13796 12656 12221 12814 14293>,
			<14117 14099 13066 12078 12696 13891>,
			<14102 14308 13320 12361 13220 13430>,
			<14067 14461 13615 12700 13684 13151>,
			<14149 14543 14244 12804 13333 13431>,
			<14474 14587 15101 12876 12685 13946>,
			<14661 14571 15612 13034 12599 13917>,
			<14693 14373 15973 13488 12779 13385>,
			<14703 14223 16095 14139 13093 13168>,
			<14696 14412 15672 15505 14103 14071>,
			<14675 14725 15107 16801 15258 14961>,
			<14621 14707 14792 16570 15958 14852>,
			<14372 14417 14482 15568 16479 14575>,
			<14166 14284 14345 15118 16344 14636>,
			<14078 14420 14020 15020 15130 15270>,
			<13901 14634 13825 15026 14382 15604>,
			<13382 14851 14423 15273 14264 15343>,
			<11907 15072 15265 15626 14249 14924>,
			<11025 15048 15671 15766 14438 14498>,
			<10828 14498 16322 15835 14807 14036>,
			<10731 14099 16731 16035 15042 13990>,
			<10756 14060 17082 17067 15212 14402>,
			<10839 14034 17358 17958 15469 14909>,
			<10880 13980 17166 18034 16442 15439>,
			<10890 13904 16746 18058 17440 15947>,
			<10902 13919 16796 18045 17248 16318>,
			<10967 14533 17141 17950 16532 16648>,
			<11059 15205 17179 17891 16397 16769>,
			<11071 15531 16882 18102 16915 16753>,
			<11050 15760 16584 18109 16604 16516>,
			<11072 15786 16203 17344 15498 16049>,
			<11136 15402 16559 17291 16235 16076>,
			<11110 14183 15330 17085 15311 16145>,
			<11212 12197 15149 13398 17741 17746>,
			<11254 12411 13841 13067 15952 16048>,
			<11284 11963 13547 15607 15064 14975>,
			<11371 11325 13536 16435 15247 14984>,
			<11476 11308 13805 14912 15598 15853>,
			<11444 11316 13898 15196 15139 15332>,
			<11556 11344 13733 15162 14866 16577>,
			<11614 11173 11797 15224 15442 16745>,
			<10436 10564 11098 16017 15803 17163>,
			<9031 9065 10322 16729 18364 18944>,
			<9031 9065 10322 16729 18364 18944>,
			<9031 9065 10322 16729 18364 18944>;
	};

	qcom,pc-temp-y6-lut {
		qcom,lut-col-legend = <(-10) 0 10 25 40 50>;
		qcom,lut-row-legend = <10000 9800 9600 9400 9200 9000>,
			<8800 8600 8400 8200 8000 7800>,
			<7600 7400 7200 7000 6800 6600>,
			<6400 6200 6000 5800 5600 5400>,
			<5200 5000 4800 4600 4400 4200>,
			<4000 3800 3600 3400 3200 3000>,
			<2800 2600 2400 2200 2000 1800>,
			<1600 1400 1200 1000 900 800>,
			<700 600 500 400 300 200>,
			<100 0>;
		qcom,lut-data = <6279 5506 5221 5048 5000 4989>,
			<6305 5510 5220 5048 5000 4988>,
			<6333 5517 5220 5049 5000 4988>,
			<6357 5526 5220 5050 5001 4988>,
			<6373 5533 5220 5051 5001 4988>,
			<6378 5535 5221 5052 5002 4989>,
			<6374 5535 5223 5054 5003 4990>,
			<6366 5535 5227 5056 5004 4991>,
			<6357 5536 5229 5058 5006 4992>,
			<6345 5538 5232 5061 5008 4993>,
			<6333 5540 5237 5064 5010 4994>,
			<6323 5542 5243 5067 5011 4996>,
			<6312 5543 5250 5070 5014 4998>,
			<6298 5539 5257 5075 5017 4999>,
			<6282 5533 5264 5081 5020 5001>,
			<6265 5527 5270 5088 5023 5004>,
			<6245 5520 5275 5096 5027 5007>,
			<6228 5512 5274 5107 5032 5011>,
			<6215 5500 5261 5123 5039 5015>,
			<6203 5490 5245 5131 5047 5020>,
			<6192 5484 5229 5122 5061 5033>,
			<6182 5479 5214 5104 5070 5043>,
			<6172 5473 5205 5084 5054 5029>,
			<6161 5467 5199 5061 5019 5001>,
			<6154 5465 5196 5052 5007 4992>,
			<6152 5464 5194 5050 5003 4990>,
			<6151 5464 5194 5050 5001 4990>,
			<6150 5464 5195 5051 5002 4990>,
			<6149 5466 5198 5053 5004 4991>,
			<6148 5466 5201 5055 5006 4993>,
			<6160 5464 5203 5057 5009 4995>,
			<6181 5463 5206 5060 5012 4997>,
			<6204 5464 5207 5066 5016 5001>,
			<6235 5466 5208 5070 5019 5005>,
			<6270 5470 5207 5070 5023 5007>,
			<6313 5479 5206 5070 5026 5009>,
			<6365 5490 5207 5068 5021 5005>,
			<6428 5507 5213 5062 5008 4995>,
			<6503 5528 5218 5057 5002 4990>,
			<6585 5548 5221 5053 5000 4987>,
			<6677 5569 5224 5052 5000 4988>,
			<6773 5595 5226 5055 5003 4991>,
			<6865 5612 5228 5053 5001 4989>,
			<6885 5589 5218 5052 5002 4989>,
			<6905 5620 5220 5046 4998 4985>,
			<7107 5705 5231 5051 5002 4990>,
			<7251 5770 5246 5058 5006 4993>,
			<7427 5863 5269 5065 5011 4998>,
			<7651 6008 5303 5073 5018 5007>,
			<7924 6244 5361 5082 5024 5011>,
			<8254 6698 5451 5077 5008 4995>,
			<8853 7755 5714 5073 5010 4996>,
			<12444 13225 6964 5090 5016 5003>,
			<36447 51437 16533 5131 5035 5021>,
			<36447 51437 16533 5131 5035 5021>,
			<36447 51437 16533 5131 5035 5021>;
	};

};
